# HDSC_HC32F480 register map
Vendor: HDSC Co.Ltd; Series: ARMCM4; File version: 1.2
CPU: CM0 r0p0, little endian, no MPU, no FPU, 3 interrupt priority bits
Registers are 16-bit, read-write, reset 0x0 unless marked. A register's access mark holds for its fields unless they carry their own. Offsets are from the block's base; [hi:lo] are bit positions; {n}, {i} and the like mark numbered series.

## MSC0_SCI — desc MSC_SCI
Base 0x40021000; alternate view of MSC0_I2C
Same registers: MSC1_SCI 0x40021100 (alternate view of MSC1_I2C), MSC2_SCI 0x40021200 (alternate view of MSC2_I2C)
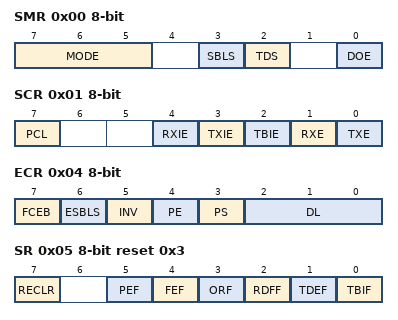
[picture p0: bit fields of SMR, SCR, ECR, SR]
0x00 SMR 8-bit
  [7:5] MODE, [3] SBLS, [2] TDS, [0] DOE
0x01 SCR 8-bit
  [7] PCL, [4] RXIE, [3] TXIE, [2] TBIE, [1] RXE, [0] TXE
0x04 ECR 8-bit
  [7] FCEB, [6] ESBLS, [5] INV, [4] PE, [3] PS, [2:0] DL
0x05 SR 8-bit ro reset 0x3
  [7] RECLR rw, [5] PEF, [4] FEF, [3] ORF, [2] RDFF, [1] TDEF, [0] TBIF
0x08 TXDR_RXDR (reset mask 0x1FF)
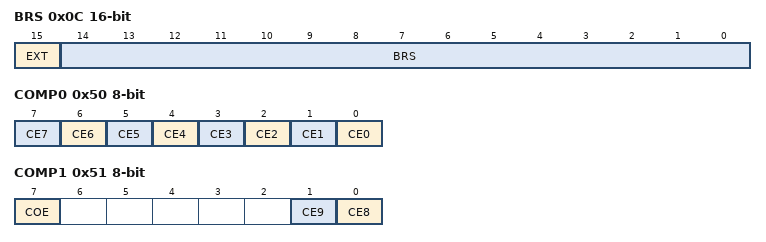
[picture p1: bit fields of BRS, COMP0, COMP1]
0x0C BRS
  [15] EXT, [14:0] BRS
0x50 COMP0 8-bit
  [n] CE{n} (n=0..7)
0x51 COMP1 8-bit
  [7] COE, [1] CE9, [0] CE8

## MSC0_SPI — desc MSC_SPI
Base 0x40021000; alternate view of MSC0_I2C
Same registers: MSC1_SPI 0x40021100 (alternate view of MSC1_I2C), MSC2_SPI 0x40021200 (alternate view of MSC2_I2C)
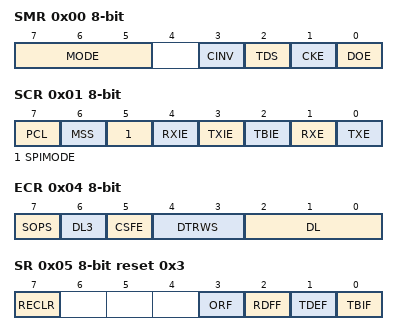
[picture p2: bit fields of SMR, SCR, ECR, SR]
0x00 SMR 8-bit
  [7:5] MODE, [3] CINV, [2] TDS, [1] CKE, [0] DOE
0x01 SCR 8-bit
  [7] PCL, [6] MSS, [5] SPIMODE, [4] RXIE, [3] TXIE, [2] TBIE, [1] RXE, [0] TXE
0x04 ECR 8-bit
  [7] SOPS, [6] DL3, [5] CSFE, [4:3] DTRWS, [2:0] DL
0x05 SR 8-bit ro reset 0x3
  [7] RECLR rw, [3] ORF, [2] RDFF, [1] TDEF, [0] TBIF
0x08 TXDR_RXDR
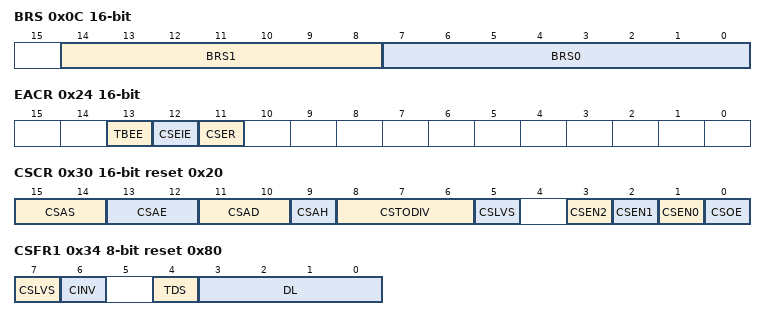
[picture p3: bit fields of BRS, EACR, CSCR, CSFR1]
0x0C BRS
  [14:8] BRS1, [7:0] BRS0
0x1C CSTMG0 8-bit
0x1D CSTMG1 8-bit
0x20 CSTMG23
0x24 EACR
  [13] TBEE, [12] CSEIE, [11] CSER
0x28 TMR ro
0x2C TMC
0x30 CSCR reset 0x20
  [15:14] CSAS, [13:12] CSAE, [11:10] CSAD, [9] CSAH, [8:6] CSTODIV, [5] CSLVS, [3] CSEN2, [2] CSEN1, [1] CSEN0, [0] CSOE
0x34 CSFR1 8-bit reset 0x80
  [7] CSLVS, [6] CINV, [4] TDS, [3:0] DL
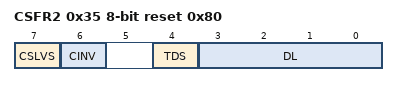
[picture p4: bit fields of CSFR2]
0x35 CSFR2 8-bit reset 0x80
  [7] CSLVS, [6] CINV, [4] TDS, [3:0] DL
0x3C TBYTE0 8-bit
0x3D TBYTE1 8-bit
0x40 TBYTE2 8-bit
0x41 TBYTE3 8-bit

## MSTP
Base 0x40048000
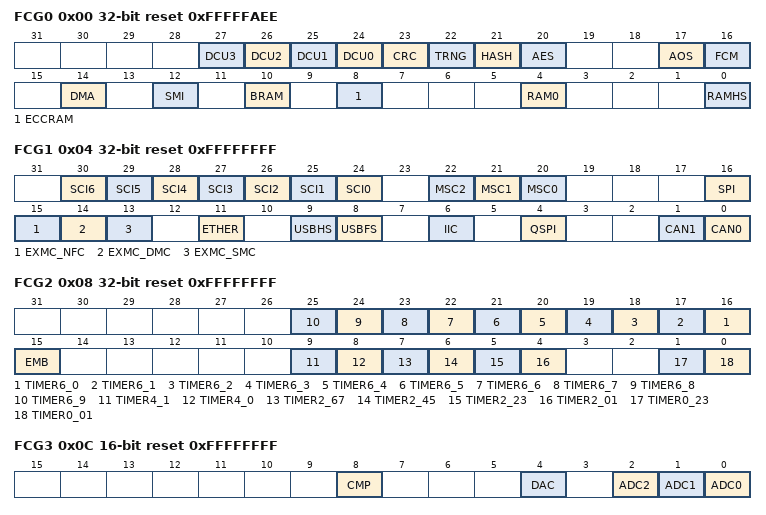
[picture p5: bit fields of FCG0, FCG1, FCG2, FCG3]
0x00 FCG0 32-bit reset 0xFFFFFAEE
  [n+24] DCU{n} (n=0..3), [23] CRC, [22] TRNG, [21] HASH, [20] AES, [17] AOS, [16] FCM, [14] DMA, [12] SMI, [10] BRAM, [8] ECCRAM, [4] RAM0, [0] RAMHS
0x04 FCG1 32-bit reset 0xFFFFFFFF
  [n+24] SCI{n} (n=0..6), [22] MSC2, [21] MSC1, [20] MSC0, [16] SPI, [15] EXMC_NFC, [14] EXMC_DMC, [13] EXMC_SMC, [11] ETHER, [9] USBHS, [8] USBFS, [6] IIC, [4] QSPI, [1] CAN1, [0] CAN0
0x08 FCG2 32-bit reset 0xFFFFFFFF
  [n+16] TIMER6_{n} (n=0..9), [15] EMB, [9] TIMER4_1, [8] TIMER4_0, [7] TIMER2_67, [6] TIMER2_45, [5] TIMER2_23, [4] TIMER2_01, [1] TIMER0_23, [0] TIMER0_01
0x0C FCG3 reset 0xFFFFFFFF
  [8] CMP, [4] DAC, [2] ADC2, [1] ADC1, [0] ADC0
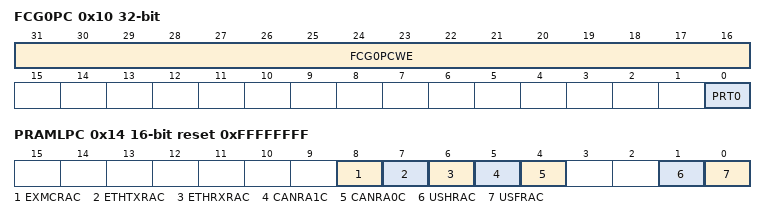
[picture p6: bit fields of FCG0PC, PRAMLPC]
0x10 FCG0PC 32-bit
  [31:16] FCG0PCWE wo, [0] PRT0
0x14 PRAMLPC reset 0xFFFFFFFF
  [8] EXMCRAC, [7] ETHTXRAC, [6] ETHRXRAC, [5] CANRA1C, [4] CANRA0C, [1] USHRAC, [0] USFRAC

## QSPI
Base 0x98000000
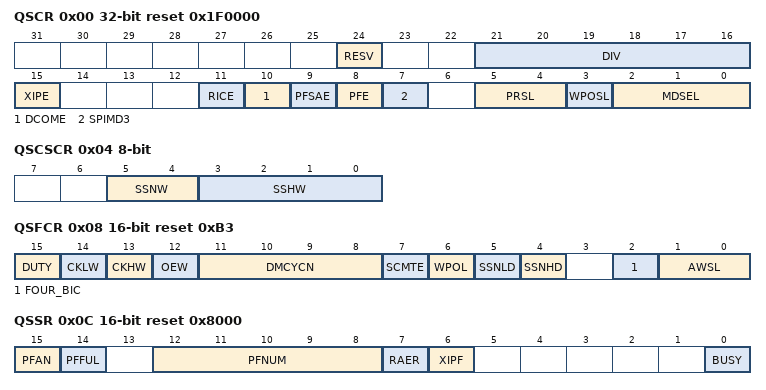
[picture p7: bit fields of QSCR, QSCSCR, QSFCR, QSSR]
0x00 QSCR 32-bit reset 0x1F0000
  [24] RESV, [21:16] DIV, [15] XIPE, [11] RICE, [10] DCOME, [9] PFSAE, [8] PFE, [7] SPIMD3, [5:4] PRSL, [3] WPOSL, [2:0] MDSEL
0x04 QSCSCR 8-bit
  [5:4] SSNW, [3:0] SSHW
0x08 QSFCR reset 0xB3
  [15] DUTY, [14] CKLW, [13] CKHW, [12] OEW, [11:8] DMCYCN, [7] SCMTE, [6] WPOL, [5] SSNLD, [4] SSNHD, [2] FOUR_BIC, [1:0] AWSL
0x0C QSSR reset 0x8000
  [15] PFAN, [14] PFFUL, [12:8] PFNUM, [7] RAER, [6] XIPF, [0] BUSY
0x10 QSDCOM 8-bit
0x14 QSCCMD 8-bit
0x18 QSXCMD 8-bit reset 0xFF
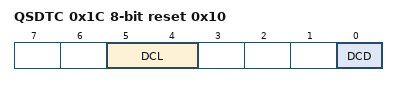
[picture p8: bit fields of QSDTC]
0x1C QSDTC 8-bit reset 0x10
  [5:4] DCL, [0] DCD
0x804 QSEXAR 32-bit
  [31:26] EXADR

## RTC
Base 0x4004BA00
0x00 CR0 8-bit
  [0] RESET
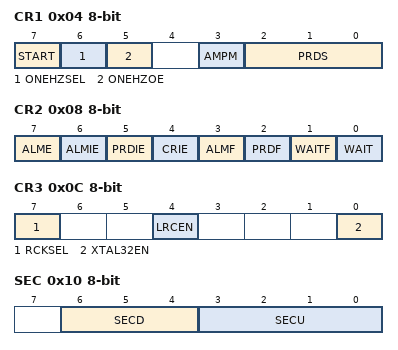
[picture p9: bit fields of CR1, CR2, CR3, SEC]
0x04 CR1 8-bit
  [7] START, [6] ONEHZSEL, [5] ONEHZOE, [3] AMPM, [2:0] PRDS
0x08 CR2 8-bit
  [7] ALME, [6] ALMIE, [5] PRDIE, [4] CRIE, [3] ALMF, [2] PRDF, [1] WAITF, [0] WAIT
0x0C CR3 8-bit
  [7] RCKSEL, [4] LRCEN, [0] XTAL32EN
0x10 SEC 8-bit
  [6:4] SECD, [3:0] SECU
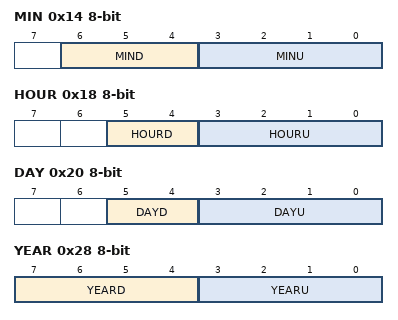
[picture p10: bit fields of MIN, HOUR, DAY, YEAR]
0x14 MIN 8-bit
  [6:4] MIND, [3:0] MINU
0x18 HOUR 8-bit
  [5:4] HOURD, [3:0] HOURU
0x1C WEEK 8-bit
  [2:0] WEEK
0x20 DAY 8-bit
  [5:4] DAYD, [3:0] DAYU
0x24 MON 8-bit
  [4:0] MON
0x28 YEAR 8-bit
  [7:4] YEARD, [3:0] YEARU
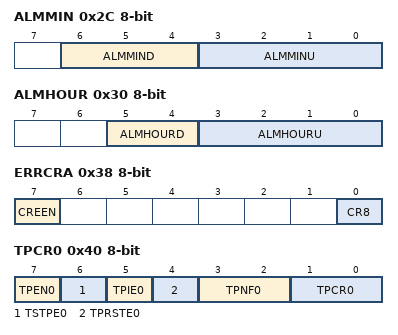
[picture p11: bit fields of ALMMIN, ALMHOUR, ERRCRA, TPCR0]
0x2C ALMMIN 8-bit
  [6:4] ALMMIND, [3:0] ALMMINU
0x30 ALMHOUR 8-bit
  [5:4] ALMHOURD, [3:0] ALMHOURU
0x34 ALMWEEK 8-bit
  [6:0] ALMWEEK
0x38 ERRCRA 8-bit
  [7] CREEN, [0] CR8
0x3C ERRCRB 8-bit
0x40 TPCR0 8-bit
  [7] TPEN0, [6] TSTPE0, [5] TPIE0, [4] TPRSTE0, [3:2] TPNF0, [1:0] TPCR0
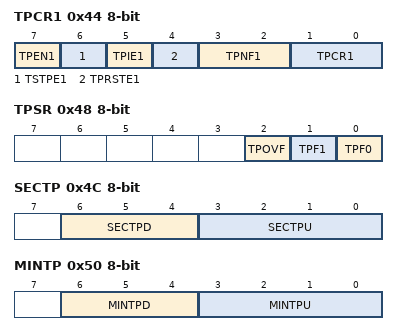
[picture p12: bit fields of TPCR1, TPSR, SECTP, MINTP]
0x44 TPCR1 8-bit
  [7] TPEN1, [6] TSTPE1, [5] TPIE1, [4] TPRSTE1, [3:2] TPNF1, [1:0] TPCR1
0x48 TPSR 8-bit
  [2] TPOVF, [1] TPF1, [0] TPF0
0x4C SECTP 8-bit
  [6:4] SECTPD, [3:0] SECTPU
0x50 MINTP 8-bit
  [6:4] MINTPD, [3:0] MINTPU
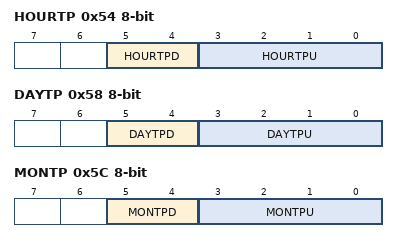
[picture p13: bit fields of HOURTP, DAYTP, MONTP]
0x54 HOURTP 8-bit
  [5:4] HOURTPD, [3:0] HOURTPU
0x58 DAYTP 8-bit
  [5:4] DAYTPD, [3:0] DAYTPU
0x5C MONTP 8-bit
  [5:4] MONTPD, [3:0] MONTPU
